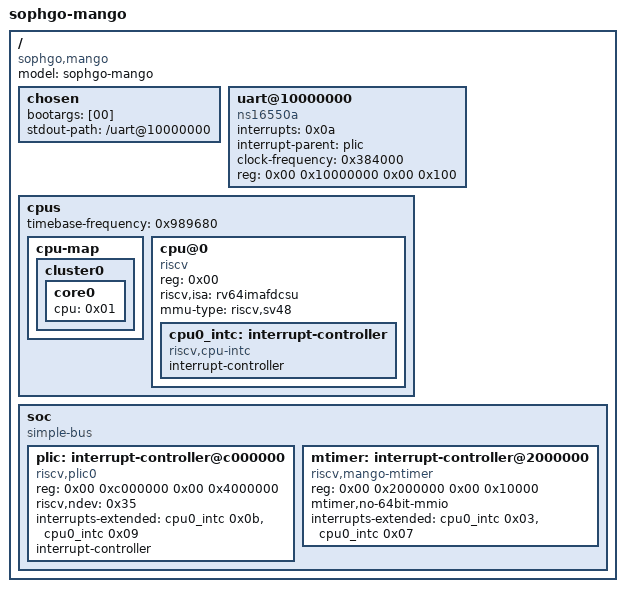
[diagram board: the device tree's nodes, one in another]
/dts-v1/;

/ {
	#address-cells = <2>;
	#size-cells = <2>;
	model = "sophgo-mango";
	compatible = "sophgo,mango";

	chosen {
		bootargs = [00];
		stdout-path = "/uart@10000000";
	};

	uart@10000000 {
		interrupts = <0x0a>;
		interrupt-parent = <&plic>;
		clock-frequency = <0x384000>;
		reg = <0x00 0x10000000 0x00 0x100>;
		compatible = "ns16550a";
	};

	cpus {
		#address-cells = <0x01>;
		#size-cells = <0x00>;
		timebase-frequency = <0x989680>;

		cpu-map {

			cluster0 {

				core0 {
					cpu = <0x01>;
				};
			};
		};

		cpu@0 {
			phandle = <0x01>;
			device_type = "cpu";
			reg = <0x00>;
			status = "okay";
			compatible = "riscv";
			riscv,isa = "rv64imafdcsu";
			mmu-type = "riscv,sv48";

			cpu0_intc: interrupt-controller {
				#interrupt-cells = <0x01>;
				interrupt-controller;
				compatible = "riscv,cpu-intc";
				phandle = <0x02>;
			};
		};
	};

	soc {
		#address-cells = <2>;
		#size-cells = <2>;
		compatible = "simple-bus";
		ranges;

		plic: interrupt-controller@c000000 {
			compatible = "riscv,plic0";
			reg = <0x00 0xc000000 0x00 0x4000000>;
			riscv,ndev = <0x35>;
			interrupts-extended = <
				&cpu0_intc 0x0b
				&cpu0_intc 0x09
				>;

			interrupt-controller;

			#interrupt-cells = <0x01>;
			#address-cells = <0x00>;
		};

		mtimer: interrupt-controller@2000000 {
			compatible = "riscv,mango-mtimer";
			reg = <0x00 0x2000000 0x00 0x10000>;
			mtimer,no-64bit-mmio;
			interrupts-extended = <
				&cpu0_intc 0x03
				&cpu0_intc 0x07
				>;
		};
	};
};
